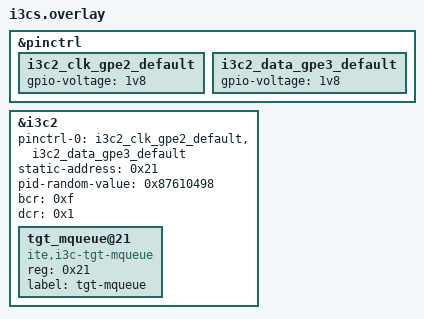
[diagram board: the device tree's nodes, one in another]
/*
 * Copyright (c) 2025 ITE Corporation. All Rights Reserved.
 *
 * SPDX-License-Identifier: Apache-2.0
 */

&pinctrl {
	i3c2_clk_gpe2_default: i3c2_clk_gpe2_default {
		gpio-voltage = "1v8";
	};
	i3c2_data_gpe3_default: i3c2_data_gpe3_default {
		gpio-voltage = "1v8";
	};
};

&i3c2 {
	status = "okay";

	pinctrl-0 = <
		     &i3c2_clk_gpe2_default
		     &i3c2_data_gpe3_default>;
	pinctrl-names = "default";
	static-address = <0x21>;
	pid-random-value = <0x87610498>;
	bcr = <0xf>; // With ibi payload
	dcr = <0x1>;

	tgt_mqueue@21 {
		compatible = "ite,i3c-tgt-mqueue";
		reg = <0x21>;
		label = "tgt-mqueue";
		status = "okay";
	};
};
